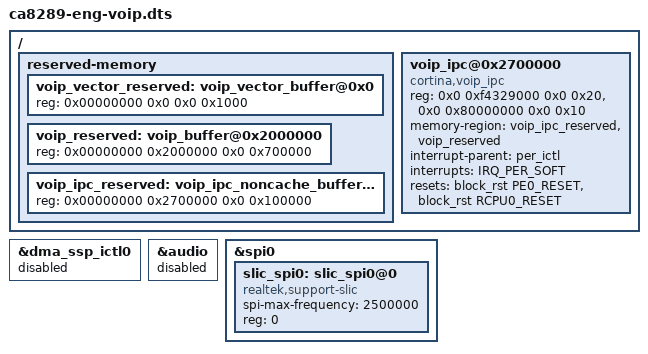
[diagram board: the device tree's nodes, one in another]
/ {
	reserved-memory {
		/* reserved memory area in DDR for Taroko eCos */
		voip_vector_reserved: voip_vector_buffer@0x0 {
			reg = <0x00000000 0x0 0x0 0x1000>;
		};

		/* reserved memory area in DDR for Taroko eCos */
		voip_reserved: voip_buffer@0x2000000 {
			 reg = <0x00000000 0x2000000 0x0 0x700000>;
		};

		voip_ipc_reserved: voip_ipc_noncache_buffer@0x2700000 {
			 reg = <0x00000000 0x2700000 0x0 0x100000>;
		};
	};

	voip_ipc@0x2700000 {
		compatible = "cortina,voip_ipc";
		reg = <0x0 0xf4329000 0x0 0x20>,
		      <0x0 0x80000000 0x0 0x10>;
		memory-region = <&voip_ipc_reserved>,
				 <&voip_reserved>;
		interrupt-parent = <&per_ictl>;
		interrupts = <IRQ_PER_SOFT>;

		resets = <&block_rst PE0_RESET>, <&block_rst RCPU0_RESET>;
		reset-names = "pe_reset", "rcpu_reset";
	};
};

&dma_ssp_ictl0 {
	/* "disabled" -> "okay" to support DSP on main CPU */
	status = "disabled";
};

&audio {
	/* "disabled" -> "okay" to support DSP on main CPU */
	status = "disabled";
};

&spi0 {
	slic_spi0: slic_spi0@0 {
		compatible = "realtek,support-slic";
		status = "okay";
		spi-max-frequency = <2500000>;
		reg = <0>;
		/* used for ISI/CSI/SPI+PCM */
		/* reset-gpio = <&gpio0 3 GPIO_ACTIVE_LOW>; */
	};
};
